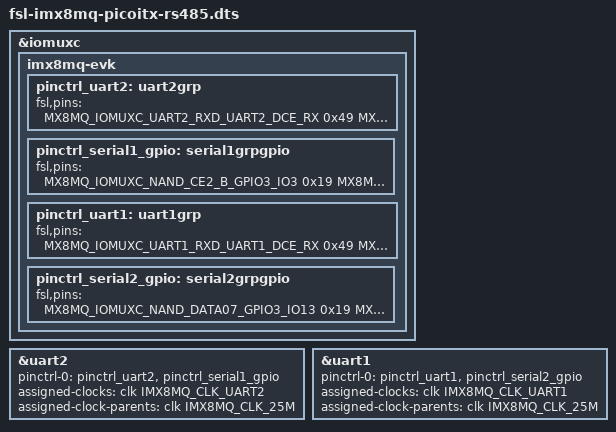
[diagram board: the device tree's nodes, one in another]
/*
 * Copyright 2017-2018 NXP
 *
 * This program is free software; you can redistribute it and/or
 * modify it under the terms of the GNU General Public License
 * as published by the Free Software Foundation; either version 2
 * of the License, or (at your option) any later version.
 *
 * This program is distributed in the hope that it will be useful,
 * but WITHOUT ANY WARRANTY; without even the implied warranty of
 * MERCHANTABILITY or FITNESS FOR A PARTICULAR PURPOSE.  See the
 * GNU General Public License for more details.
 */

#include "fsl-imx8mq-picoitx.dts"

&iomuxc {
	imx8mq-evk {
		pinctrl_uart2: uart2grp {
			fsl,pins = <
				MX8MQ_IOMUXC_UART2_RXD_UART2_DCE_RX 0x49
				MX8MQ_IOMUXC_UART2_TXD_UART2_DCE_TX 0x49
				MX8MQ_IOMUXC_UART4_RXD_GPIO5_IO28  	0x49
			>;
		};

		pinctrl_serial1_gpio: serial1grpgpio {
            fsl,pins = <
                MX8MQ_IOMUXC_NAND_CE2_B_GPIO3_IO3   0x19
                MX8MQ_IOMUXC_NAND_CE3_B_GPIO3_IO4   0x19
                MX8MQ_IOMUXC_NAND_DQS_GPIO3_IO14    0x19
                MX8MQ_IOMUXC_NAND_RE_B_GPIO3_IO15   0x19
                MX8MQ_IOMUXC_NAND_READY_B_GPIO3_IO16    0x19
                MX8MQ_IOMUXC_NAND_WE_B_GPIO3_IO17   0x19
                MX8MQ_IOMUXC_NAND_WP_B_GPIO3_IO18   0x19
            >;
        };

		pinctrl_uart1: uart1grp {
			fsl,pins = <
				MX8MQ_IOMUXC_UART1_RXD_UART1_DCE_RX	0x49
				MX8MQ_IOMUXC_UART1_TXD_UART1_DCE_TX	0x49
				MX8MQ_IOMUXC_UART3_RXD_GPIO5_IO26	0x49
			>;
		};

		pinctrl_serial2_gpio: serial2grpgpio {
            fsl,pins = <
                MX8MQ_IOMUXC_NAND_DATA07_GPIO3_IO13 0x19
                MX8MQ_IOMUXC_NAND_DATA06_GPIO3_IO12 0x19
                MX8MQ_IOMUXC_NAND_DATA05_GPIO3_IO11 0x19
                MX8MQ_IOMUXC_NAND_DATA04_GPIO3_IO10 0x19
                MX8MQ_IOMUXC_NAND_DATA03_GPIO3_IO9  0x19
                MX8MQ_IOMUXC_NAND_DATA02_GPIO3_IO8  0x19
                MX8MQ_IOMUXC_NAND_DATA01_GPIO3_IO7  0x19
            >;
        };
	};
};

multi_protocol_serial1: &uart2 {
    pinctrl-names = "default";
    pinctrl-0 = <&pinctrl_uart2>, <&pinctrl_serial1_gpio>;
    assigned-clocks = <&clk IMX8MQ_CLK_UART2>;
    assigned-clock-parents = <&clk IMX8MQ_CLK_25M>;
    status = "okay";
};

multi_protocol_serial2: &uart1 {
    pinctrl-names = "default";
    pinctrl-0 = <&pinctrl_uart1>, <&pinctrl_serial2_gpio>;
    assigned-clocks = <&clk IMX8MQ_CLK_UART1>;
    assigned-clock-parents = <&clk IMX8MQ_CLK_25M>;
    status = "okay";
};
